AUTOSAR XML (schema 314)
package /ComponentType
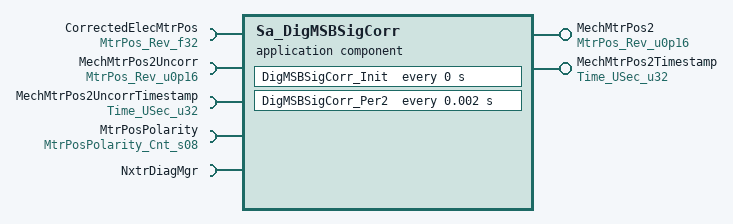
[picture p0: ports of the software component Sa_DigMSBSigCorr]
  application software component type Sa_DigMSBSigCorr
    provide port MechMtrPos2: unqueued-sender-com-spec{data-element=Rev_u0p16, can-invalidate=false, init-value=D_ZERO_CNT_U16}, provided-interface=MtrPos_Rev_u0p16
    provide port MechMtrPos2Timestamp: unqueued-sender-com-spec{data-element=USec_u32, can-invalidate=false, init-value=D_ZERO_CNT_U32}, provided-interface=Time_USec_u32
    5 x require port:
      CorrectedElecMtrPos: unqueued-receiver-com-spec{data-element=Rev_f32, init-value=D_ZERO_ULS_F32}, required-interface=MtrPos_Rev_f32
      MechMtrPos2Uncorr: unqueued-receiver-com-spec{data-element=Rev_u0p16, init-value=D_ZERO_CNT_U16}, required-interface=MtrPos_Rev_u0p16
      MechMtrPos2UncorrTimestamp: unqueued-receiver-com-spec{data-element=USec_u32, init-value=D_ZERO_CNT_U32}, required-interface=Time_USec_u32
      MtrPosPolarity: unqueued-receiver-com-spec{data-element=Cnt_s08, init-value=D_ZERO_CNT_S8}, required-interface=MtrPosPolarity_Cnt_s08
      NxtrDiagMgr: required-com-specs=[GetNTCActive, GetNTCFailed, GetNTCStatus, SetNTCStatus], required-interface=NxtrDiagMgr
  internal behavior Sa_DigMSBSigCorr_InternalBehavior: component=Sa_DigMSBSigCorr
    timing event DigMSBSigCorr_InitEvent: start-on-event=DigMSBSigCorr_Init, period=0
    timing event TMT_DigMSBSigCorr_Per2: start-on-event=DigMSBSigCorr_Per2, period=0.002
    per instance memory DigMSBEOLData: type=DigMSBEOLType, type-definition=/DataType/DigMSBEOLType
    port-api-options:
      enable-take-address=false, indirect-api=false, port=CorrectedElecMtrPos
      enable-take-address=false, indirect-api=false, port=MechMtrPos2
      enable-take-address=false, indirect-api=false, port=MechMtrPos2Timestamp
      enable-take-address=false, indirect-api=false, port=MechMtrPos2Uncorr
      enable-take-address=false, indirect-api=false, port=MechMtrPos2UncorrTimestamp
      enable-take-address=false, indirect-api=false, port=MtrPosPolarity
      enable-take-address=false, indirect-api=false, port=NxtrDiagMgr
    runnable DigMSBSigCorr_Init
      sync call SC_NxtrDiagMgr_SetNTCStatus: operation=NxtrDiagMgr.SetNTCStatus, timeout=0
    runnable DigMSBSigCorr_Per2
      4 x data read access:
        READ_CorrectedElecMtrPos_Rev_f32: data-element=CorrectedElecMtrPos.Rev_f32
        READ_MechMtrPos2Uncorr_Rev_u0p16: data-element=MechMtrPos2Uncorr.Rev_u0p16
        READ_MechMtrPos2UncorrTimestamp_USec_u32: data-element=MechMtrPos2UncorrTimestamp.USec_u32
        READ_MtrPosPolarity_Cnt_s08: data-element=MtrPosPolarity.Cnt_s08
      data write access WRITE_MechMtrPos2_Rev_u0p16: data-element=MechMtrPos2.Rev_u0p16
      data write access WRITE_MechMtrPos2Timestamp_USec_u32: data-element=MechMtrPos2Timestamp.USec_u32
      sync call SC_NxtrDiagMgr_SetNTCStatus: operation=NxtrDiagMgr.SetNTCStatus, timeout=0
    service-needss:
      swc nv block needs DigMSBEOLBlk: n-data-sets=0, readonly=false, reliability=LOW, resistant-to-changed-sw=false, restore-at-start=false, write-only-once=false, writing-frequency=0, writing-priority=LOW, mirror-block=DigMSBEOLData
  swc implementation Sa_DigMSBSigCorr_Implementation: behavior=Sa_DigMSBSigCorr_InternalBehavior
    code-descriptors:
      code Code: type=SRC
